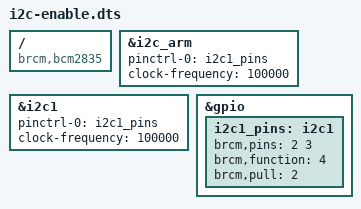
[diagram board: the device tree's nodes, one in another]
/dts-v1/;
/plugin/;

/ {
    compatible = "brcm,bcm2835";
    
    fragment@0 {
        target = <&i2c_arm>;
        __overlay__ {
            status = "okay";
            pinctrl-names = "default";
            pinctrl-0 = <&i2c1_pins>;
            clock-frequency = <100000>;
        };
    };

    fragment@1 {
        target = <&i2c1>;
        __overlay__ {
            status = "okay";
            pinctrl-names = "default";
            pinctrl-0 = <&i2c1_pins>;
            clock-frequency = <100000>;
        };
    };

    fragment@2 {
        target = <&gpio>;
        __overlay__ {
            i2c1_pins: i2c1 {
                brcm,pins = <2 3>;
                brcm,function = <4>; /* ALT0 */
                brcm,pull = <2>; /* Pull-up */
            };
        };
    };
};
